# STM32F070F6P6 register map
File version: 1.0
Registers are 32-bit, access not given, reset 0x0 unless marked. A register's access mark holds for its fields unless they carry their own. Offsets are from the block's base; [hi:lo] are bit positions; {n}, {i} and the like mark numbered series; 'fields as' and 'values as' point back to an identical list.

## SPI1
Base 0x40013000
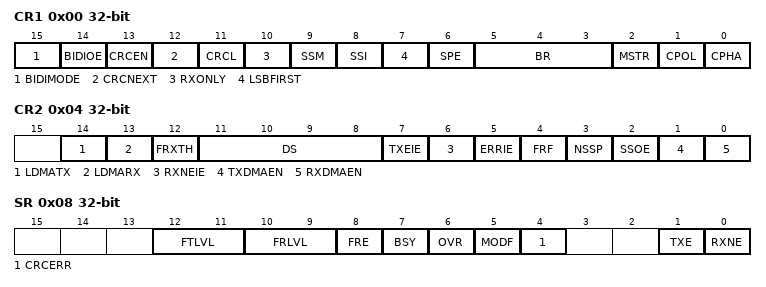
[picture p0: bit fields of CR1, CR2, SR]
0x00 CR1
  [15] BIDIMODE, [14] BIDIOE, [13] CRCEN, [12] CRCNEXT, [11] CRCL, [10] RXONLY, [9] SSM, [8] SSI, [7] LSBFIRST, [6] SPE, [5:3] BR, [2] MSTR, [1] CPOL, [0] CPHA
0x04 CR2
  [14] LDMATX, [13] LDMARX, [12] FRXTH, [11:8] DS, [7] TXEIE, [6] RXNEIE, [5] ERRIE, [4] FRF, [3] NSSP, [2] SSOE, [1] TXDMAEN, [0] RXDMAEN
0x08 SR
  [12:11] FTLVL, [10:9] FRLVL, [8] FRE, [7] BSY, [6] OVR, [5] MODF, [4] CRCERR, [1] TXE, [0] RXNE
0x0C DR
0x10 CRCPR
  [31:0] CRCPOLY
0x14 RXCRCR
  [31:0] RXCRC
0x18 TXCRCR
  [31:0] TXCRC
0x1C I2SCFGR
  [11] I2SMOD

## DBGMCU
Base 0x40015800
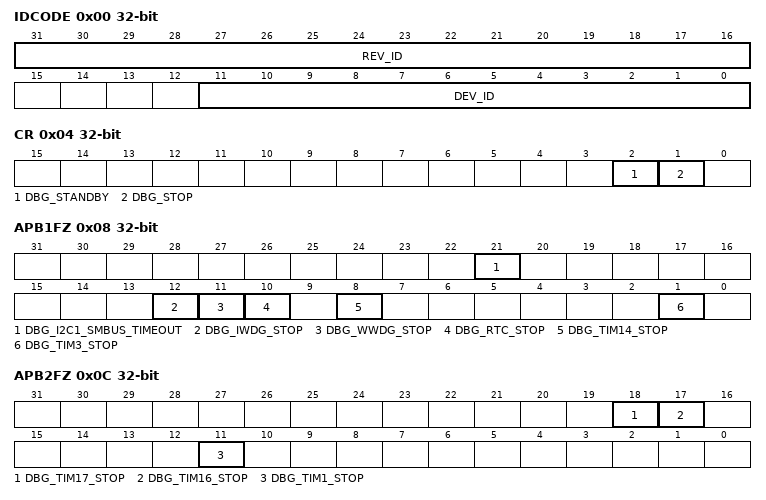
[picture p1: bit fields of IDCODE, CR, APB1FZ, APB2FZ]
0x00 IDCODE
  [31:16] REV_ID, [11:0] DEV_ID
0x04 CR
  [2] DBG_STANDBY, [1] DBG_STOP
0x08 APB1FZ
  [21] DBG_I2C1_SMBUS_TIMEOUT, [12] DBG_IWDG_STOP, [11] DBG_WWDG_STOP, [10] DBG_RTC_STOP, [8] DBG_TIM14_STOP, [1] DBG_TIM3_STOP
0x0C APB2FZ
  [18] DBG_TIM17_STOP, [17] DBG_TIM16_STOP, [11] DBG_TIM1_STOP

## DMA1
Base 0x40020000
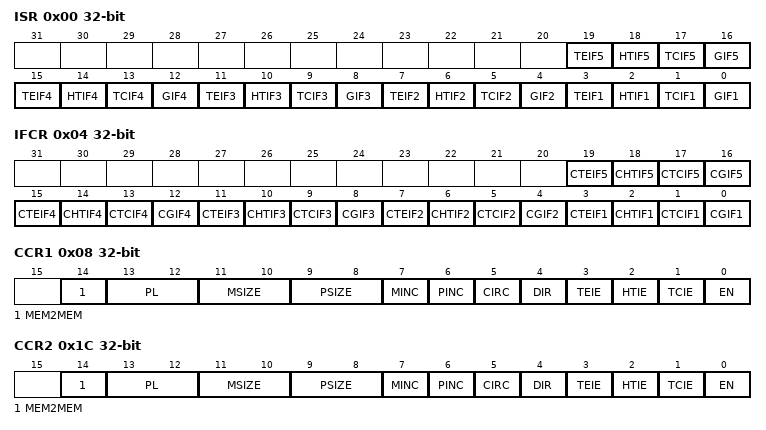
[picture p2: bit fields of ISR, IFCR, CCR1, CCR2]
0x00 ISR
  [4n-1] TEIF{n} (n=1..5), [4n-2] HTIF{n} (n=1..5), [4n-3] TCIF{n} (n=1..5), [4n-4] GIF{n} (n=1..5)
0x04 IFCR
  [4n-1] CTEIF{n} (n=1..5), [4n-2] CHTIF{n} (n=1..5), [4n-3] CTCIF{n} (n=1..5), [4n-4] CGIF{n} (n=1..5)
0x08 CCR1
  [14] MEM2MEM, [13:12] PL, [11:10] MSIZE, [9:8] PSIZE, [7] MINC, [6] PINC, [5] CIRC, [4] DIR, [3] TEIE, [2] HTIE, [1] TCIE, [0] EN
0x0C CNDTR1
  [15:0] NDT
0x10 CPAR1
  [31:0] PA
{0x0+0x14*i} CMAR{i} (i=1..5)
  [31:0] MA
0x1C CCR2
  fields as CCR1
0x20 CNDTR2
  [15:0] NDT
0x24 CPAR2
  [31:0] PA
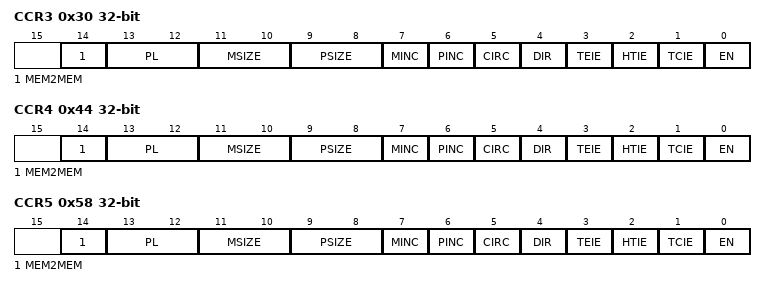
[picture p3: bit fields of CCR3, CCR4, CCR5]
0x30 CCR3
  fields as CCR1
0x34 CNDTR3
  [15:0] NDT
0x38 CPAR3
  [31:0] PA
0x44 CCR4
  fields as CCR1
0x48 CNDTR4
  [15:0] NDT
0x4C CPAR4
  [31:0] PA
0x58 CCR5
  fields as CCR1
0x5C CNDTR5
  [15:0] NDT
0x60 CPAR5
  [31:0] PA

## RCC
Base 0x40021000
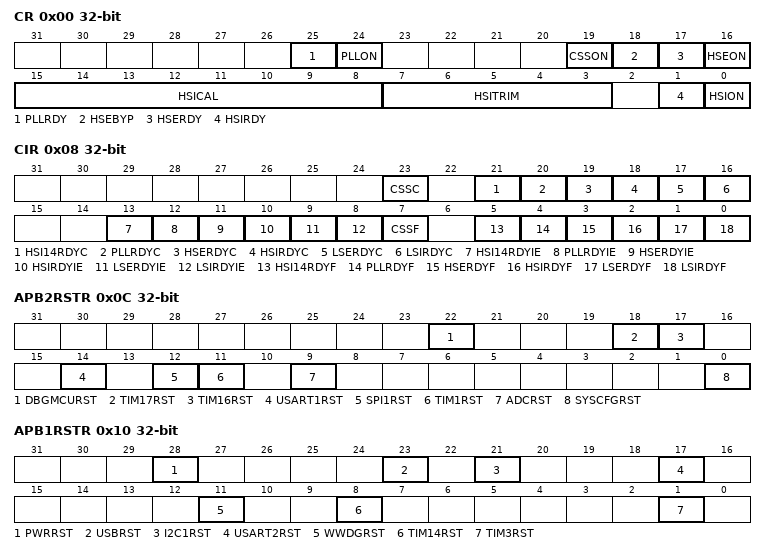
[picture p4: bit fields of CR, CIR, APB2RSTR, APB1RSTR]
0x00 CR
  [25] PLLRDY, [24] PLLON, [19] CSSON, [18] HSEBYP, [17] HSERDY, [16] HSEON, [15:8] HSICAL, [7:3] HSITRIM, [1] HSIRDY, [0] HSION
0x04 CFGR
  [31] PLLNODIV, [30:28] MCOPRE, [27:24] MCO, [22] USBPRE, [21:18] PLLMUL, [17] PLLXTPRE, [16:15] PLLSRC, [14] ADCPRE, [10] PPRE_DIV2, [10:9] PPRE_DIV8, [10:8] PPRE_DIV4, [7:4] HPRE, [3:2] SWS, [1:0] SW
0x08 CIR
  [23] CSSC, [21] HSI14RDYC, [20] PLLRDYC, [19] HSERDYC, [18] HSIRDYC, [17] LSERDYC, [16] LSIRDYC, [13] HSI14RDYIE, [12] PLLRDYIE, [11] HSERDYIE, [10] HSIRDYIE, [9] LSERDYIE, [8] LSIRDYIE, [7] CSSF, [5] HSI14RDYF, [4] PLLRDYF, [3] HSERDYF, [2] HSIRDYF, [1] LSERDYF, [0] LSIRDYF
0x0C APB2RSTR
  [22] DBGMCURST, [18] TIM17RST, [17] TIM16RST, [14] USART1RST, [12] SPI1RST, [11] TIM1RST, [9] ADCRST, [0] SYSCFGRST
0x10 APB1RSTR
  [28] PWRRST, [23] USBRST, [21] I2C1RST, [17] USART2RST, [11] WWDGRST, [8] TIM14RST, [1] TIM3RST
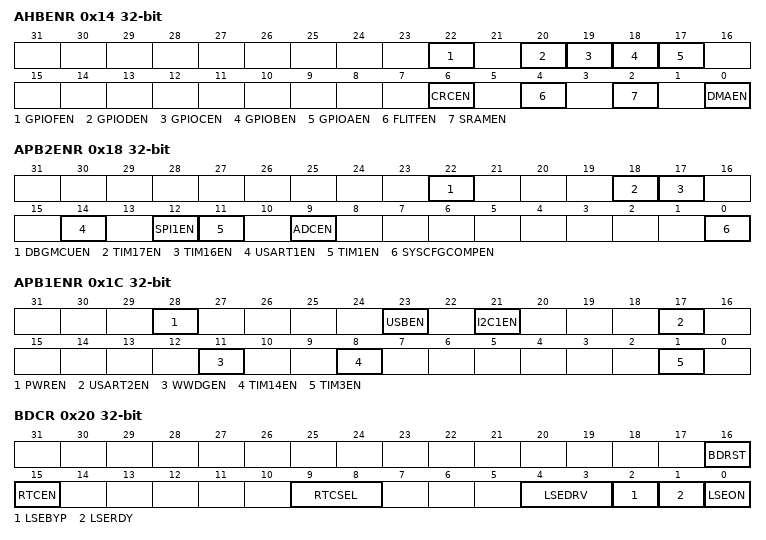
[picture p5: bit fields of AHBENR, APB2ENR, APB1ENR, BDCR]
0x14 AHBENR
  [22] GPIOFEN, [20] GPIODEN, [19] GPIOCEN, [18] GPIOBEN, [17] GPIOAEN, [6] CRCEN, [4] FLITFEN, [2] SRAMEN, [0] DMAEN
0x18 APB2ENR
  [22] DBGMCUEN, [18] TIM17EN, [17] TIM16EN, [14] USART1EN, [12] SPI1EN, [11] TIM1EN, [9] ADCEN, [0] SYSCFGCOMPEN
0x1C APB1ENR
  [28] PWREN, [23] USBEN, [21] I2C1EN, [17] USART2EN, [11] WWDGEN, [8] TIM14EN, [1] TIM3EN
0x20 BDCR
  [16] BDRST, [15] RTCEN, [9:8] RTCSEL, [4:3] LSEDRV, [2] LSEBYP, [1] LSERDY, [0] LSEON
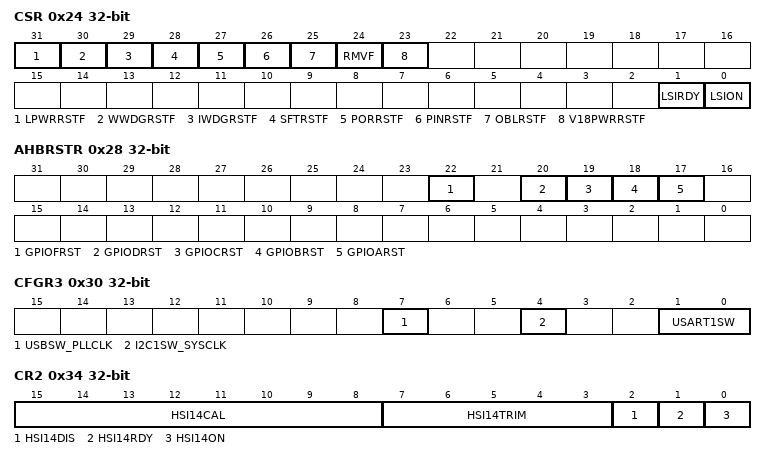
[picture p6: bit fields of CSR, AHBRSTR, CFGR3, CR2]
0x24 CSR
  [31] LPWRRSTF, [30] WWDGRSTF, [29] IWDGRSTF, [28] SFTRSTF, [27] PORRSTF, [26] PINRSTF, [25] OBLRSTF, [24] RMVF, [23] V18PWRRSTF, [1] LSIRDY, [0] LSION
0x28 AHBRSTR
  [22] GPIOFRST, [20] GPIODRST, [19] GPIOCRST, [18] GPIOBRST, [17] GPIOARST
0x2C CFGR2
  [3:0] PREDIV
0x30 CFGR3
  [7] USBSW_PLLCLK, [4] I2C1SW_SYSCLK, [1:0] USART1SW
0x34 CR2
  [15:8] HSI14CAL, [7:3] HSI14TRIM, [2] HSI14DIS, [1] HSI14RDY, [0] HSI14ON

## FLASH
Base 0x40022000
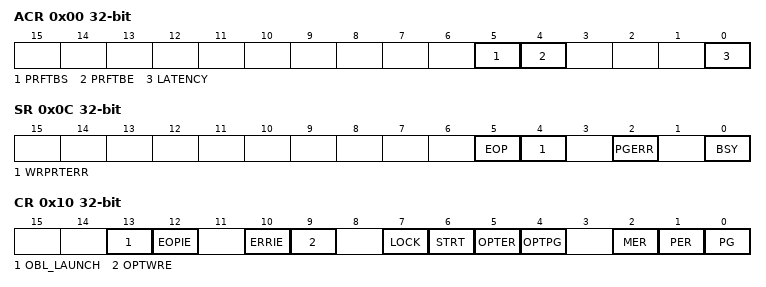
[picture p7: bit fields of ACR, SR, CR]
0x00 ACR
  [5] PRFTBS, [4] PRFTBE, [0] LATENCY
0x04 KEYR
  [31:0] FKEYR
0x08 OPTKEYR
0x0C SR
  [5] EOP, [4] WRPRTERR, [2] PGERR, [0] BSY
0x10 CR
  [13] OBL_LAUNCH, [12] EOPIE, [10] ERRIE, [9] OPTWRE, [7] LOCK, [6] STRT, [5] OPTER, [4] OPTPG, [2] MER, [1] PER, [0] PG
0x14 AR
  [31:0] FAR
0x1C OBR
  [31:24] DATA1, [23:16] DATA0, [14] RAM_PARITY_CHECK, [13] VDDA_MONITOR, [12] nBOOT1, [10] nRST_STDBY, [9] nRST_STOP, [14:8] USER, [2] RDPRT2, [1] RDPRT1, [0] OPTERR
0x20 WRPR
  [15:0] WRP

## CRC
Base 0x40023000
0x00 DR
0x04 IDR 8-bit
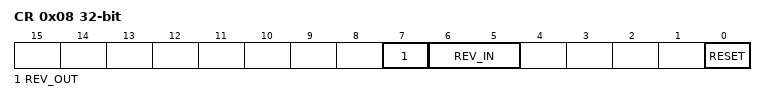
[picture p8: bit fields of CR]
0x08 CR
  [7] REV_OUT, [6:5] REV_IN, [0] RESET
0x10 INIT

## GPIOA
Base 0x48000000
Same registers: GPIOB 0x48000400, GPIOC 0x48000800, GPIOD 0x48000C00, GPIOF 0x48001400
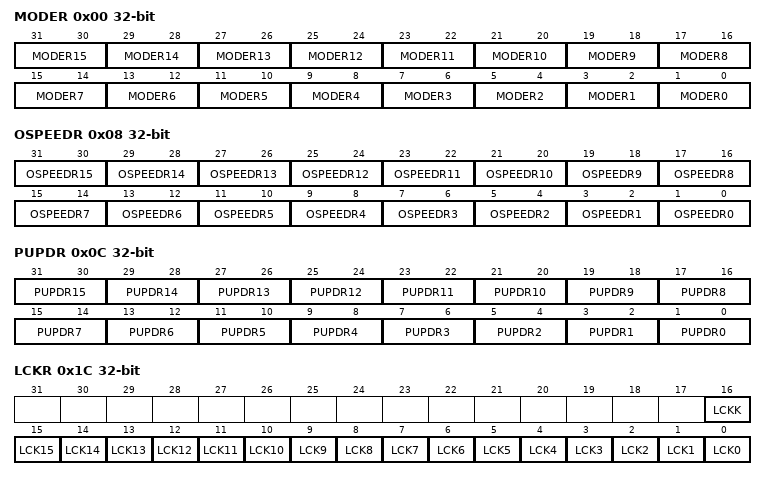
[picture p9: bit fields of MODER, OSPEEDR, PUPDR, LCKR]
0x00 MODER
  [2n+1:2n] MODER{n} (n=0..15)
0x04 OTYPER
0x08 OSPEEDR
  [2n+1:2n] OSPEEDR{n} (n=0..15)
0x0C PUPDR
  [2n+1:2n] PUPDR{n} (n=0..15)
0x10 IDR
0x14 ODR
0x18 BSRR
0x1C LCKR
  [16] LCKK, [n] LCK{n} (n=0..15)
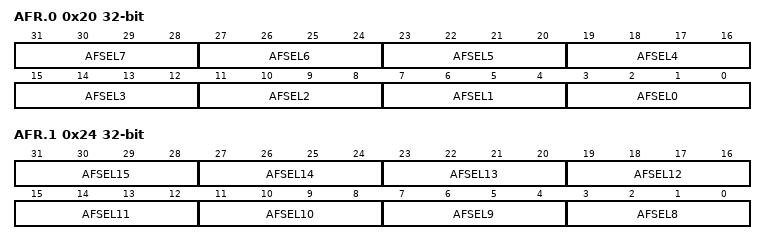
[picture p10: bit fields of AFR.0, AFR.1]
0x20 AFR.0
  [4n+3:4n] AFSEL{n} (n=0..7)
0x24 AFR.1
  [4n-29:4n-32] AFSEL{n} (n=8..15)
0x28 BRR
